# haltium_bbpr register map
Vendor: Nordic Semiconductor; Series: nRFHaltium; File version: 1
Registers are 32-bit, read-write, reset 0x0 unless marked. A register's access mark holds for its fields unless they carry their own. Offsets are from the block's base; [hi:lo] are bit positions; 'fields as' and 'values as' point back to an identical list.

## GLOBAL_TDDCONF_S — TDDCONF
Base 0xBF001000
0x400 SYSPWRUPREQ — System power-up request
  [0] ACTIVE — Activate power-up request
    0=NotActive (Power-up request not active); 1=Active (Power-up request active)
0x404 DBGPWRUPREQ — Debug power-up request
  fields as SYSPWRUPREQ
0x408 TRACEPORTSPEED — Trace port trace clock speed
  [1:0] SPEED — Trace clock speed
    0=Speed25MHz; 1=Speed12500KHz (Speed 12.5MHz); 2=Speed6250KHz (Speed 6.25MHz); 3=Speed3125KHz (Speed 3.125MHz)
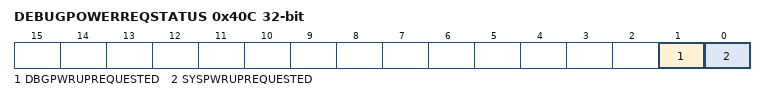
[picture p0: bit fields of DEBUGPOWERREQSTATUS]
0x40C DEBUGPOWERREQSTATUS ro — Combined effective system status of both SWJ-DP and TDDCONF registers originated power requests
  [1] DBGPWRUPREQUESTED — Debug domain powerup request status
    0=NoPowerReq (Power not requested); 1=Power requested
  [0] SYSPWRUPREQUESTED — System powerup request status
    0=NoPowerReq (Power not requested); 1=Power requested

## GLOBAL_TBM_NS — Trace buffer monitor 0
Base 0xBF003000
Same registers: GLOBAL_TBM_S 0xBF003000 (alternate view of GLOBAL_TBM_NS)
0x00 TASKS_START wo — Start counter
  [0] TASKS_START
    1=Trigger task
0x04 TASKS_STOP wo — Stop counter, clear counter value
  [0] TASKS_STOP
    1=Trigger task
0x08 TASKS_FLUSH wo — Stop counter, keep current counter value
  [0] TASKS_FLUSH
    1=Trigger task
0x100 EVENTS_HALFFULL — Counter value equals half-full
  [0] EVENTS_HALFFULL
    0=NotGenerated (Event not generated); 1=Generated (Event generated)
0x104 EVENTS_FULL — Counter value equals full
  [0] EVENTS_FULL
    values as EVENTS_HALFFULL.EVENTS_HALFFULL
0x108 EVENTS_FLUSH — Counter stopped due to flush
  [0] EVENTS_FLUSH
    values as EVENTS_HALFFULL.EVENTS_HALFFULL
0x200 SHORTS — Shortcuts between local events and tasks
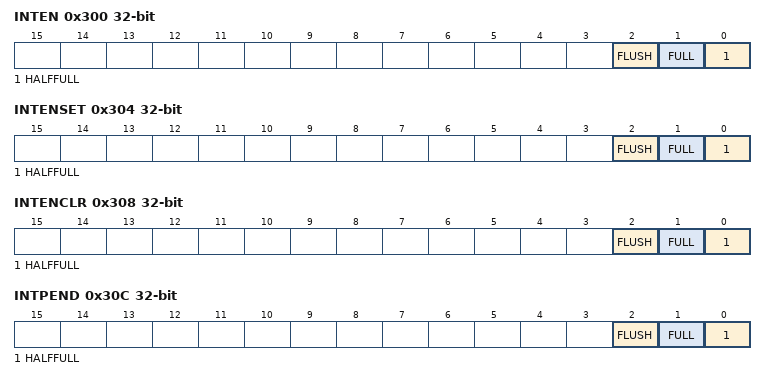
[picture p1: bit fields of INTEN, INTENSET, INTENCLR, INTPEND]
0x300 INTEN — Enable or disable interrupt
  [all] fields
    0=Disabled; 1=Enabled
  [2] FLUSH — Enable or disable interrupt for event FLUSH
  [1] FULL — Enable or disable interrupt for event FULL
  [0] HALFFULL — Enable or disable interrupt for event HALFFULL
0x304 INTENSET — Enable interrupt
  [all] fields
    on read: 0=Disabled (Read: Disabled); 1=Enabled (Read: Enabled) | on write: 1=Set (Enable)
  [2] FLUSH — Write '1' to enable interrupt for event FLUSH
  [1] FULL — Write '1' to enable interrupt for event FULL
  [0] HALFFULL — Write '1' to enable interrupt for event HALFFULL
0x308 INTENCLR — Disable interrupt
  [all] fields
    on read: 0=Disabled (Read: Disabled); 1=Enabled (Read: Enabled) | on write: 1=Clear (Disable)
  [2] FLUSH — Write '1' to disable interrupt for event FLUSH
  [1] FULL — Write '1' to disable interrupt for event FULL
  [0] HALFFULL — Write '1' to disable interrupt for event HALFFULL
0x30C INTPEND ro — Pending interrupts
  [all] fields
    on read: 0=NotPending (Read: Not pending); 1=Pending (Read: Pending)
  [2] FLUSH — Read pending status of interrupt for event FLUSH
  [1] FULL — Read pending status of interrupt for event FULL
  [0] HALFFULL — Read pending status of interrupt for event HALFFULL
0x400 BUFFERSIZE reset 0x1FF — System RAM trace buffer total size in bytes
  [11:0] BUFFERSIZE — Must only be configured in STOP mode. Must be multiple of 16 bytes to make half-buffer size always 64 bit word aligned. BUFFERSIZE LSB byte always fixed as 0xF to 16 bytes boundary. Minimum BUFFERSIZE value 0x00F i.e. 16 bytes, maximum value 0xFFF i.e. 4096 bytes.
    15=Min (16 bytes); 0xFFF=Max (4096 bytes)
0x404 COUNT ro — Counter current value
  [11:0] COUNT

## GLOBAL_TSGEN_NS — GENERIC 0
Base 0xBF041000
Same registers: GLOBAL_ETB_NS 0xBF044000, GLOBAL_ETR_NS 0xBF045000
0x00 TASKS_GENERICTASK wo — Generic event
  [0] TASKS_GENERICTASK
    1=Trigger task
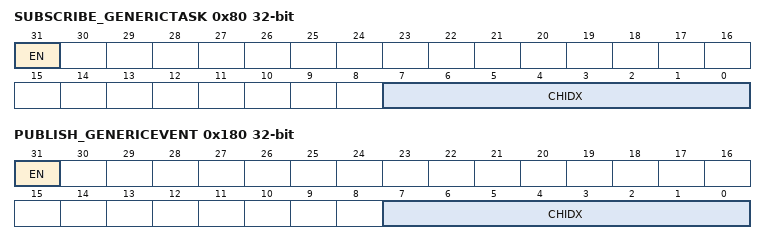
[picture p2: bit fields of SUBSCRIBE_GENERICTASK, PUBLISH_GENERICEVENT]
0x80 SUBSCRIBE_GENERICTASK — Subscribe configuration for task GENERICTASK
  [31] EN
    0=Disabled (Disable subscription); 1=Enabled (Enable subscription)
  [7:0] CHIDX — DPPI channel that task GENERICTASK will subscribe to
0x100 EVENTS_GENERICEVENT — Generic event
  [0] EVENTS_GENERICEVENT
    0=NotGenerated (Event not generated); 1=Generated (Event generated)
0x180 PUBLISH_GENERICEVENT — Publish configuration for event GENERICEVENT
  [31] EN
    0=Disabled (Disable publishing); 1=Enabled (Enable publishing)
  [7:0] CHIDX — DPPI channel that event GENERICEVENT will publish to
0x300 INTEN — Enable or disable interrupt
  [0] GENERICEVENT — Enable or disable interrupt for event GENERICEVENT
    0=Disabled; 1=Enabled
0x304 INTENSET — Enable interrupt
  [0] GENERICEVENT — Write '1' to enable interrupt for event GENERICEVENT
    on read: 0=Disabled (Read: Disabled); 1=Enabled (Read: Enabled) | on write: 1=Set (Enable)
0x308 INTENCLR — Disable interrupt
  [0] GENERICEVENT — Write '1' to disable interrupt for event GENERICEVENT
    on read: 0=Disabled (Read: Disabled); 1=Enabled (Read: Enabled) | on write: 1=Clear (Disable)

## Notices in the file
Copyright (c) 2010 - 2020, Nordic Semiconductor ASA
All rights reserved.
Redistribution and use in source and binary forms, with or without modification,
are permitted provided that the following conditions are met:
1. Redistributions of source code must retain the above copyright notice, this
list of conditions and the following disclaimer.
2. Redistributions in binary form, except as embedded into a Nordic
Semiconductor ASA integrated circuit in a product or a software update for
such product, must reproduce the above copyright notice, this list of
conditions and the following disclaimer in the documentation and/or other
materials provided with the distribution.
3. Neither the name of Nordic Semiconductor ASA nor the names of its
contributors may be used to endorse or promote products derived from this
software without specific prior written permission.
4. This software, with or without modification, must only be used with a
Nordic Semiconductor ASA integrated circuit.
5. Any software provided in binary form under this license must not be reverse
engineered, decompiled, modified and/or disassembled.
THIS SOFTWARE IS PROVIDED BY NORDIC SEMICONDUCTOR ASA "AS IS" AND ANY EXPRESS
OR IMPLIED WARRANTIES, INCLUDING, BUT NOT LIMITED TO, THE IMPLIED WARRANTIES
OF MERCHANTABILITY, NONINFRINGEMENT, AND FITNESS FOR A PARTICULAR PURPOSE ARE
DISCLAIMED. IN NO EVENT SHALL NORDIC SEMICONDUCTOR ASA OR CONTRIBUTORS BE
LIABLE FOR ANY DIRECT, INDIRECT, INCIDENTAL, SPECIAL, EXEMPLARY, OR
CONSEQUENTIAL DAMAGES (INCLUDING, BUT NOT LIMITED TO, PROCUREMENT OF SUBSTITUTE
GOODS OR SERVICES; LOSS OF USE, DATA, OR PROFITS; OR BUSINESS INTERRUPTION)
HOWEVER CAUSED AND ON ANY THEORY OF LIABILITY, WHETHER IN CONTRACT, STRICT
LIABILITY, OR TORT (INCLUDING NEGLIGENCE OR OTHERWISE) ARISING IN ANY WAY OUT
OF THE USE OF THIS SOFTWARE, EVEN IF ADVISED OF THE POSSIBILITY OF SUCH DAMAGE.
